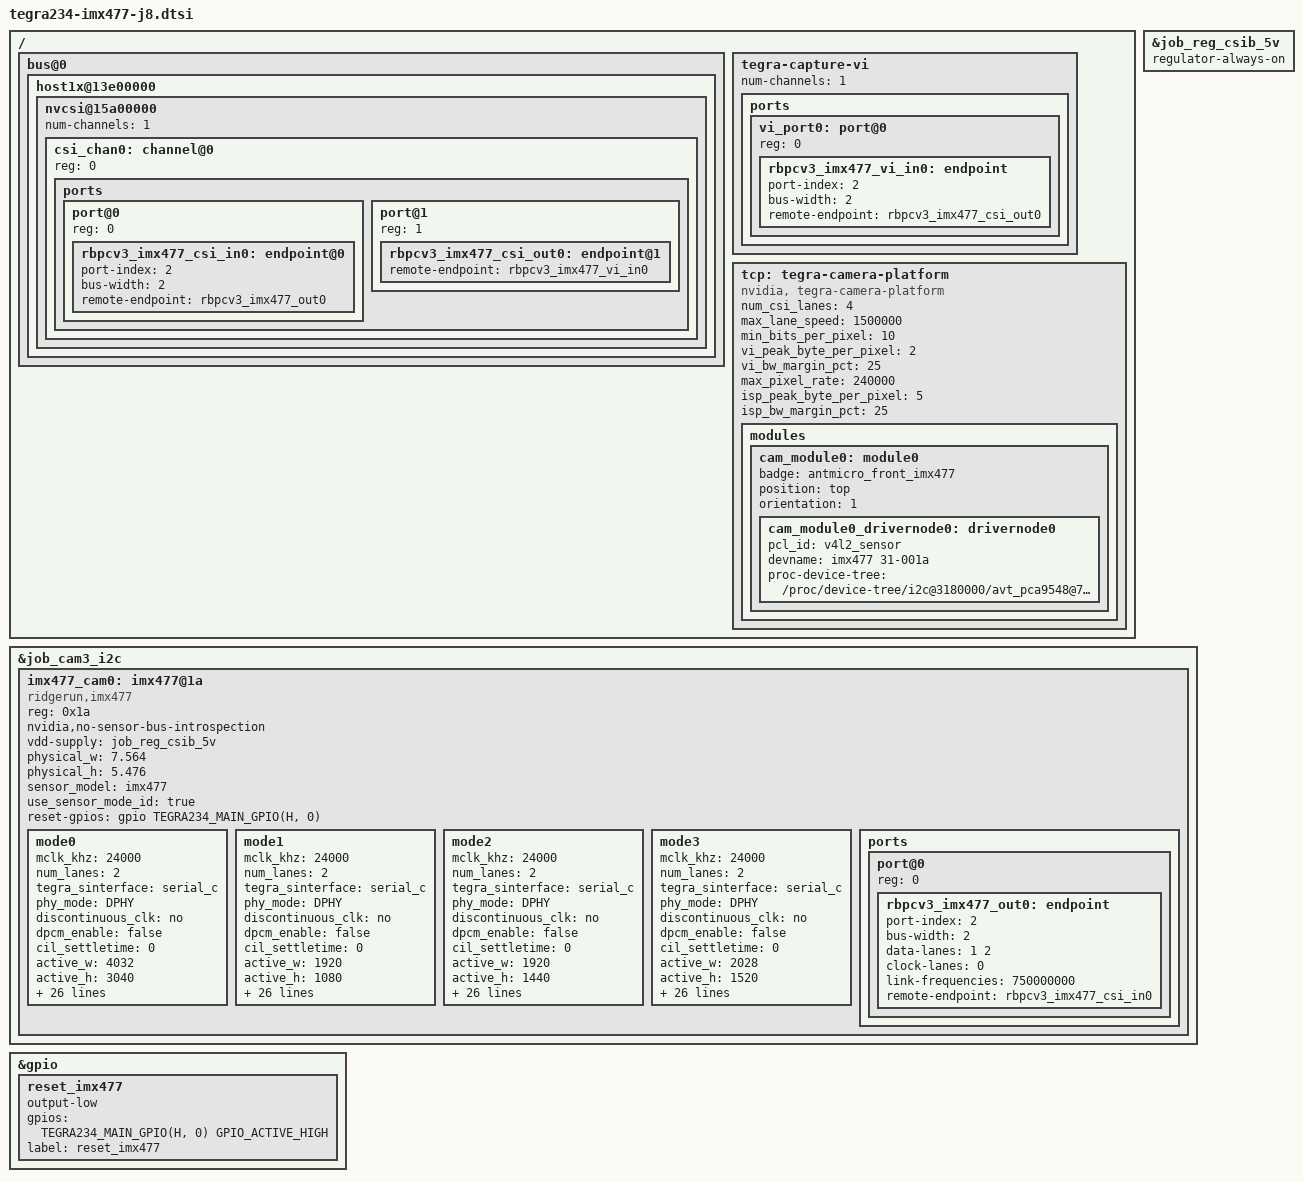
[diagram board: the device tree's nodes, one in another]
/*
 * Copyright (c) 2022, NVIDIA CORPORATION.  All rights reserved.
 * Copyright (c) 2023 Antmicro <www.antmicro.com>
 * Copyright (c) 2026, University of Washington
 *
 * This program is free software; you can redistribute it and/or modify
 * it under the terms of the GNU General Public License as published by
 * the Free Software Foundation; either version 2 of the License, or
 * (at your option) any later version.
 *
 * This program is distributed in the hope that it will be useful, but WITHOUT
 * ANY WARRANTY; without even the implied warranty of MERCHANTABILITY or
 * FITNESS FOR A PARTICULAR PURPOSE.  See the GNU General Public License for
 * more details.
 *
 * You should have received a copy of the GNU General Public License
 * along with this program.  If not, see <http://www.gnu.org/licenses/>.
 */

/*
 * This DTSI file implements support for a single Raspberry Pi HQ (IMX477)
 * camera connected to the J8 connector on the 
 * Antmicro Jetson Orin Baseboard (JOB) via a Capable Robot 
 * Y-flex cable
 *
 * We use only 2 lanes for the camera
 *
 * ====== Power management ======
 * CSI A and CSA B connectors feature GPIO-controlled 5V and 3V3 power
 * supplies. Alvium cameras use the 5V rails, controlled by following regulators:
 * - job_reg_csia_5v for CSI A
 * - job_reg_csib_5v for CSI B
 *
 * From the CapableRobot site:
 * The 15-pin camera cable has footprints which allow a level shifter to
 * connect the VSYNC / trigger pin of the NX Baseboard to either GPIO of 
 * the connected camera. But by default, these level shifters are NOT 
 * installed as most Raspberry PI cameras do not support external 
 * triggering – but a level shifter MOSFET is shipped with your order to 
 * install at Q1 or Q2 if needed. A 10K resistor is installed at R1,
 * which pulls up pin 11 (the IO pin nearer the CSI pins), as this 
 * pin is commonly an enable input for camera power.
 *
 * !!! By default, VSYNC_CAM2 is not connected on the Antmicro baseboard
 *
 *   R2 / R4 are used to configure GPIO12.   From the factory, R2
 *           is populated, configuring it as a GPIO output and disconnecting
 *           VSYNC_CAM2
 *   Inputs and output of level shifter have 10k pullups
 *   so VSYNC_CAM2_3V3 is forced high by default
 *
 *   Notes to self on operation of the reset circuit on the Pi HQ modules:
 *      The IMX477 XCLR signal is pulled up (enabled) by default.
 *
 *      The APX803 reset controller pulls the /RESET output low (open collector)
 *          for a fixed time each time Vcc exceeds a given threshold
 *
 *      By default R7 is not populated.  If it is populated, the APX803
 *          is powered and performs its expected function
 *
 *     If R8 is popuated, the VSYNC input powers R8.  This is why it must be
 *          removed on 1.8V jetson output headers;   the 1.8V is not enough to
 *          to enable the APX803
 * 
 *      If the APX803 is _not_ powered (R7 and R8 removed), the pull up resistor
 *          enables the camera by default
 *
 * As the Antmicro board has built-in level shifters, the FET is not required
 * in the flex.
 *
 * NOTE:   Unfortunately, the current Capable robot flex circuits connect
 * camera to the camera3 position (job_cam3_i2c and CSI_D).   By default
 * this is _not connected_ on the Antmicro board.  This can be fixed by
 * updating the routing resistors for the CSI bus or cutting a custom flex
 * which uses Cameras 2 (job_cam2_i2c and CSI_B)
 *
 * ====== I2C routing ======
 * - Camera 2: SCL/SDA_CAM2 (job_cam2_i2c)
 * - Camera 3: SCL/SDA_CAM3 (job_cam3_i2c)
 *
 * ====== CSI lane mapping ======
 * - Camera 2: CSI1 = CSI_B [CLK, D0, D1]
 * - Camera 3: CSI2 = CSI_D n/p by default, used to 4x camera 1
 *
 * ====== CSI lane polarity ======
 *
 * See Jetson Orin NX Design Guide DG-10931-001 fig.10-1.:
 * - CSI0_D1 is inverted on SoM
 * - CSI1_D0 is inverted on SoM
 */


&job_reg_csib_5v {
	/* @trisect This forces the regulator ON and keeps it on */
	regulator-always-on;
};

 &job_cam3_i2c {

	imx477_cam0: imx477@1a {
		compatible = "ridgerun,imx477";
		/* I2C device address */
		reg = <0x1a>;
		nvidia,no-sensor-bus-introspection;
		vdd-supply = <&job_reg_csib_5v>;

		/* V4L2 device node location */
		//devnode = "video0";

		/* Physical dimensions of sensor */
		physical_w = "7.564";
		physical_h = "5.476";

		sensor_model = "imx477";

		use_sensor_mode_id = "true";

		// Technically, this isn't connected...
		reset-gpios = <&gpio TEGRA234_MAIN_GPIO(H, 0) GPIO_ACTIVE_HIGH>; 

		mode0 { /* IMX477_MODE_4032X3040 */
			mclk_khz = "24000";
			num_lanes = "2";
			tegra_sinterface = "serial_c";
			phy_mode = "DPHY";
			discontinuous_clk = "no";
			dpcm_enable = "false";
			cil_settletime = "0";

			active_w = "4032";
			active_h = "3040";
			mode_type = "bayer";
			pixel_phase = "rggb";
			csi_pixel_bit_depth = "10";
			readout_orientation = "90";
			line_length = "9024";
			inherent_gain = "1";
			mclk_multiplier = "80";
			pix_clk_hz = "840000000";

			gain_factor = "16";
			framerate_factor = "1000000";
			exposure_factor = "1000000";
			min_gain_val = "16"; /* 1.00x */
			max_gain_val = "356"; /* 22x */
			step_gain_val = "1";
			default_gain = "16"; /* 1.00x */
			min_hdr_ratio = "1";
			max_hdr_ratio = "1";
			min_framerate = "2000000"; /* 2.0 fps */
			max_framerate = "30000000"; /* 30.0 fps */
			step_framerate = "1";
			default_framerate = "30000000"; /* 30.0 fps */
			min_exp_time = "13"; /* us */
			max_exp_time = "683709"; /* us */
			step_exp_time = "1";
			default_exp_time = "2495"; /* us */

			embedded_metadata_height = "2";
		};
		mode1 { /* IMX477_MODE_1920X1080 */
			mclk_khz = "24000";
			num_lanes = "2";
			tegra_sinterface = "serial_c";
			phy_mode = "DPHY";
			discontinuous_clk = "no";
			dpcm_enable = "false";
			cil_settletime = "0";

			active_w = "1920";
			active_h = "1080";
			mode_type = "bayer";
			pixel_phase = "rggb";
			csi_pixel_bit_depth = "10";
			readout_orientation = "90";
			line_length = "9024";
			inherent_gain = "1";
			mclk_multiplier = "80";
			pix_clk_hz = "840000000";

			gain_factor = "16";
			framerate_factor = "1000000";
			exposure_factor = "1000000";
			min_gain_val = "16"; /* 1.00x */
			max_gain_val = "356"; /* 22x */
			step_gain_val = "1";
			default_gain = "16"; /* 1.00x */
			min_hdr_ratio = "1";
			max_hdr_ratio = "1";
			min_framerate = "2000000"; /* 2.0 fps */
			max_framerate = "60000000"; /* 60.0 fps */
			step_framerate = "1";
			default_framerate = "60000000"; /* 60.0 fps */
			min_exp_time = "13"; /* us */
			max_exp_time = "683709"; /* us */
			step_exp_time = "1";
			default_exp_time = "2495"; /* us */

			embedded_metadata_height = "2";
		};
		mode2 { /* IMX477_MODE_1920X1440 */
			mclk_khz = "24000";
			num_lanes = "2";
			tegra_sinterface = "serial_c";
			phy_mode = "DPHY";
			discontinuous_clk = "no";
			dpcm_enable = "false";
			cil_settletime = "0";

			active_w = "1920";
			active_h = "1440";
			mode_type = "bayer";
			pixel_phase = "rggb";
			csi_pixel_bit_depth = "10";
			readout_orientation = "90";
			line_length = "6524";
			inherent_gain = "1";
			mclk_multiplier = "80";
			pix_clk_hz = "840000000";

			gain_factor = "16";
			framerate_factor = "1000000";
			exposure_factor = "1000000";
			min_gain_val = "16"; /* 1.00x */
			max_gain_val = "356"; /* 22x */
			step_gain_val = "1";
			default_gain = "16"; /* 1.00x */
			min_hdr_ratio = "1";
			max_hdr_ratio = "1";
			min_framerate = "2000000"; /* 2.0 fps */
			max_framerate = "60000000"; /* 60.0 fps */
			step_framerate = "1";
			default_framerate = "60000000"; /* 60.0 fps */
			min_exp_time = "13"; /* us */
			max_exp_time = "683709"; /* us */
			step_exp_time = "1";
			default_exp_time = "2495"; /* us */

			embedded_metadata_height = "2";
		};
		mode3 { /* IMX477_MODE_2028X1520 */
			mclk_khz = "24000";
			num_lanes = "2";
			tegra_sinterface = "serial_c";
			phy_mode = "DPHY";
			discontinuous_clk = "no";
			dpcm_enable = "false";
			cil_settletime = "0";

			active_w = "2028";
			active_h = "1520";
			mode_type = "bayer";
			pixel_phase = "rggb";
			csi_pixel_bit_depth = "10";
			readout_orientation = "90";
			line_length = "6524";
			inherent_gain = "1";
			mclk_multiplier = "80";
			pix_clk_hz = "840000000";

			gain_factor = "16";
			framerate_factor = "1000000";
			exposure_factor = "1000000";
			min_gain_val = "16"; /* 1.00x */
			max_gain_val = "356"; /* 22x */
			step_gain_val = "1";
			default_gain = "16"; /* 1.00x */
			min_hdr_ratio = "1";
			max_hdr_ratio = "1";
			min_framerate = "2000000"; /* 2.0 fps */
			max_framerate = "60000000"; /* 60.0 fps */
			step_framerate = "1";
			default_framerate = "60000000"; /* 60.0 fps */
			min_exp_time = "13"; /* us */
			max_exp_time = "683709"; /* us */
			step_exp_time = "1";
			default_exp_time = "2495"; /* us */

			embedded_metadata_height = "2";
		};

		ports {
			#address-cells = <1>;
			#size-cells = <0>;
			port@0 {
				reg = <0>;
				rbpcv3_imx477_out0: endpoint {
					port-index = <2>;
					bus-width = <2>;
					// Following copied from AVT configuration.
					// Not tested yet.
					data-lanes = <1 2>;
					clock-lanes = <0>;
					link-frequencies = /bits/ 64 <750000000>;
					remote-endpoint = <&rbpcv3_imx477_csi_in0>;
				};
			};
		};
	};
};


&gpio {
	reset_imx477 {
		output-low;
		gpios = <TEGRA234_MAIN_GPIO(H, 0) GPIO_ACTIVE_HIGH>;
		label = "reset_imx477";
		status = "okay";
	};
};

/ {

	bus@0 {
		host1x@13e00000 {
			nvcsi@15a00000 {

				num-channels = <1>;
				#address-cells = <1>;
				#size-cells = <0>;
				csi_chan0: channel@0 {
					reg = <0>;
					status = "okay";

					ports {
						#address-cells = <1>;
						#size-cells = <0>;
						port@0 {
							reg = <0>;
							status = "okay";
							rbpcv3_imx477_csi_in0: endpoint@0 {
								port-index = <2>;
								bus-width = <2>;
								remote-endpoint = <&rbpcv3_imx477_out0>;
							};
						};
						port@1 {
							reg = <1>;
							status = "okay";
							rbpcv3_imx477_csi_out0: endpoint@1 {
								status = "okay";
								remote-endpoint = <&rbpcv3_imx477_vi_in0>;
							};
						};
					};
				};
			};
		};
	};


	tegra-capture-vi {

		num-channels = <1>;
		ports {
			#address-cells = <1>;
			#size-cells = <0>;
			vi_port0: port@0 {
				reg = <0>;
				status = "okay";

				rbpcv3_imx477_vi_in0: endpoint {
					status = "okay";
					port-index = <2>;
					bus-width = <2>;
					remote-endpoint = <&rbpcv3_imx477_csi_out0>;
				};
			};
		};
	};

	// New
	tcp: tegra-camera-platform {
		compatible = "nvidia, tegra-camera-platform";
		/**
		* Physical settings to calculate max ISO BW
		*
		* num_csi_lanes = <>;
		* Total number of CSI lanes when all cameras are active
		*
		* max_lane_speed = <>;
		* Max lane speed in Kbit/s
		*
		* min_bits_per_pixel = <>;
		* Min bits per pixel
		*
		* vi_peak_byte_per_pixel = <>;
		* Max byte per pixel for the VI ISO case
		*
		* vi_bw_margin_pct = <>;
		* Vi bandwidth margin in percentage
		*
		* max_pixel_rate = <>;
		* Max pixel rate in Kpixel/s for the ISP ISO case
		*
		* isp_peak_byte_per_pixel = <>;
		* Max byte per pixel for the ISP ISO case
		*
		* isp_bw_margin_pct = <>;
		* Isp bandwidth margin in percentage
		*/
		num_csi_lanes = <4>;
		max_lane_speed = <1500000>;
		min_bits_per_pixel = <10>;
		vi_peak_byte_per_pixel = <2>;
		vi_bw_margin_pct = <25>;
		max_pixel_rate = <240000>;
		isp_peak_byte_per_pixel = <5>;
		isp_bw_margin_pct = <25>;

		/**
		 * The general guideline for naming badge_info contains 3 parts, and is as follows,
		 * The first part is the camera_board_id for the module; if the module is in a FFD
		 * platform, then use the platform name for this part.
		 * The second part contains the position of the module, ex. "rear" or "front".
		 * The third part contains the last 6 characters of a part number which is found
		 * in the module's specsheet from the vendor.
		 */
		modules {

			cam_module0: module0 {
				badge = "antmicro_front_imx477";
				position = "top";
				orientation = "1";
				status = "okay";
				cam_module0_drivernode0: drivernode0 {
					status = "okay";
					pcl_id = "v4l2_sensor";
					devname = "imx477 31-001a";
					proc-device-tree = "/proc/device-tree/i2c@3180000/avt_pca9548@70/i2c@2/imx477@1a";
				};
			};
		};
	};
};
